# RA register map
Vendor: Renesas; Series: All Chips; File version: x.xx
Registers are 32-bit, read-write, reset 0x0 unless marked. A register's access mark holds for its fields unless they carry their own. Offsets are from the block's base; [hi:lo] are bit positions; {n}, {i} and the like mark numbered series.

## R_DAC — D/A Converter
Base 0x4005E000
{0x0+2i} DADR[{i}] (i=0..1) 16-bit — D/A Data Register
  [15:0] DADR — D/A Data RegisterNOTE: When DADPR.DPSEL = 0, the high-order 4 bits are fixed to 0: right justified format. When DADPR.DPSEL = 1, the low-order 4 bits are fixed to 0: left justified format.
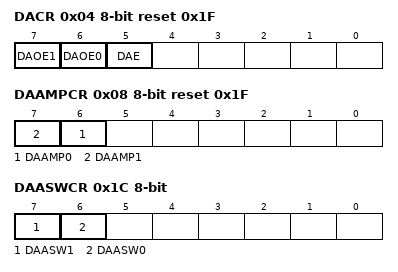
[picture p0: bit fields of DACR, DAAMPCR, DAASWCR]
0x04 DACR 8-bit reset 0x1F — D/A Control Register
  [n+6] DAOE{n} (n=0..1) — D/A Output Enable 0
    0=Analog output of channel 0 (DA0) is disabled; 1=D/A conversion of channel 0 is enabled. Analog output of channel 0 (DA0) is enabled.
  [5] DAE — D/A Enable
    0=Control D/A conversion of channels 0 and 1 individually
0x05 DADPR 8-bit — DADR0 Format Select Register
  [7] DPSEL — DADRm Format Select
    0=Right justified format; 1=Left justified format
0x06 DAADSCR 8-bit — D/A-A/D Synchronous Start Control Register
  [7] DAADST — D/A-A/D Synchronous Conversion
    0=D/A converter operation does not synchronize with A/D converter operation (unit 1) (countermeasure against interference between D/A and A/D conversions is disabled); 1=D/A converter operation synchronizes with A/D converter operation (unit 1) (countermeasure against interference between D/A and A/D conversions is enabled)
0x07 DAVREFCR 8-bit — D/A VREF Control Register
  [2:0] REF — D/A Reference Voltage Select
    0=Not selected; 1=AVCC0/AVSS0; 3=Internal reference voltage/AVSS0; 6=VREFH/VREFL; other=others (Setting prohibited)
0x08 DAAMPCR 8-bit reset 0x1F — D/A Output Amplifier Control Register
  [n+6] DAAMP{n} (n=0..1) — Amplifier Control
    0=Do not use channel output amplifier
0x09 DAPC 8-bit — D/A Switch Charge Pump Control Register
  [0] PUMPEN — Charge Pump Enable
    0=Charge pump disabled; 1=Charge pump enabled
0x1C DAASWCR 8-bit — D/A Amplifier Stabilization Wait Control Register
  [7] DAASW1 — Set the DAASW1 bit to 1 in the initialization procedure to wait for stabilization of the output amplifier of D/A channel 1. When DAASW1 is set to 1, D/A conversion operates, but the conversion result D/A is not output from channel 1. When the DAASW1 bit is 0, the stabilization wait time stops, and the D/A conversion result of channel 1 is output through the output amplifier.
    0=Amplifier stabilization wait off (output) for channel 1; 1=Amplifier stabilization wait on (high-Z) for channel 1
  [6] DAASW0 — Set the DAASW0 bit to 1 in the initialization procedure to wait for stabilization of the output amplifier of D/A channel 0. When DAASW0 is set to 1, D/A conversion operates, but the conversion result D/A is not output from channel 0. When the DAASW0 bit is 0, the stabilization wait time stops, and the D/A conversion result of channel 0 is output through the output amplifier.
    0=Amplifier stabilization wait off (output) for channel 0; 1=Amplifier stabilization wait on (high-Z) for channel 0
0x10C0 DAADUSR 8-bit — D/A A/D Synchronous Unit Select Register
  [6] AMADSEL1 — The DAADUSR register selects the target ADC12 unit for D/A and A/D synchronous conversions. Set bit [1] to 1 to select unit 1 as the target synchronous unit for the MCU. When setting the DAADSCR.DAADST bit to 1 for synchronous conversions, select the target unit in this register in advance. Only set the DAADUSR register while the ADCSR.ADST bit of the ADC12 is set to 0 and the DAADSCR.DAADST bit is set to 0.
    0=Do not select unit 1; 1=Select unit 1

## R_DAC8 — 8-Bit D/A Converter
Base 0x4009E000
{0x0+i} DACS[{i}] (i=0..1) 8-bit — D/A Conversion Value Setting Register {i}
  [7:0] DACS — DACS D/A conversion store data
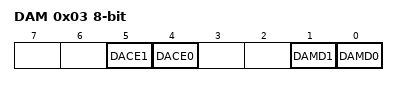
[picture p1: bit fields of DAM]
0x03 DAM 8-bit — D/A Converter Mode Register
  [5] DACE1 — D/A operation enable 1
    0=D/A conversion disabled for channel 1; 1=D/A conversion enabled for channel 1
  [4] DACE0 — D/A operation enable 0
    0=D/A conversion disabled for channel 0; 1=D/A conversion enabled for channel 0
  [1] DAMD1 — D/A operation mode select 1
    0=Channel 1 for normal operation mode; 1=Channel 1 for real-time output mode(event link)
  [0] DAMD0 — D/A operation mode select 0
    0=Channel 0 for normal operation mode; 1=Channel 0 for real-time output mode(event link)
0x06 DACADSCR 8-bit — D/A A/D Synchronous Start Control Register
  [0] DACADST — D/A A/D Synchronous Conversion
    0=Do not synchronize DAC8 with ADC16 operation (disable interference reduction between D/A and A/D conversion); 1=Synchronize DAC8 with ADC16 operation (enable interference reduction between D/A and A/D conversion)
0x07 DACPC 8-bit — D/A SW Charge Pump Control Register
  [0] PUMPEN — Charge pump enable
    0=Charge pump disable; 1=Charge pump enable
